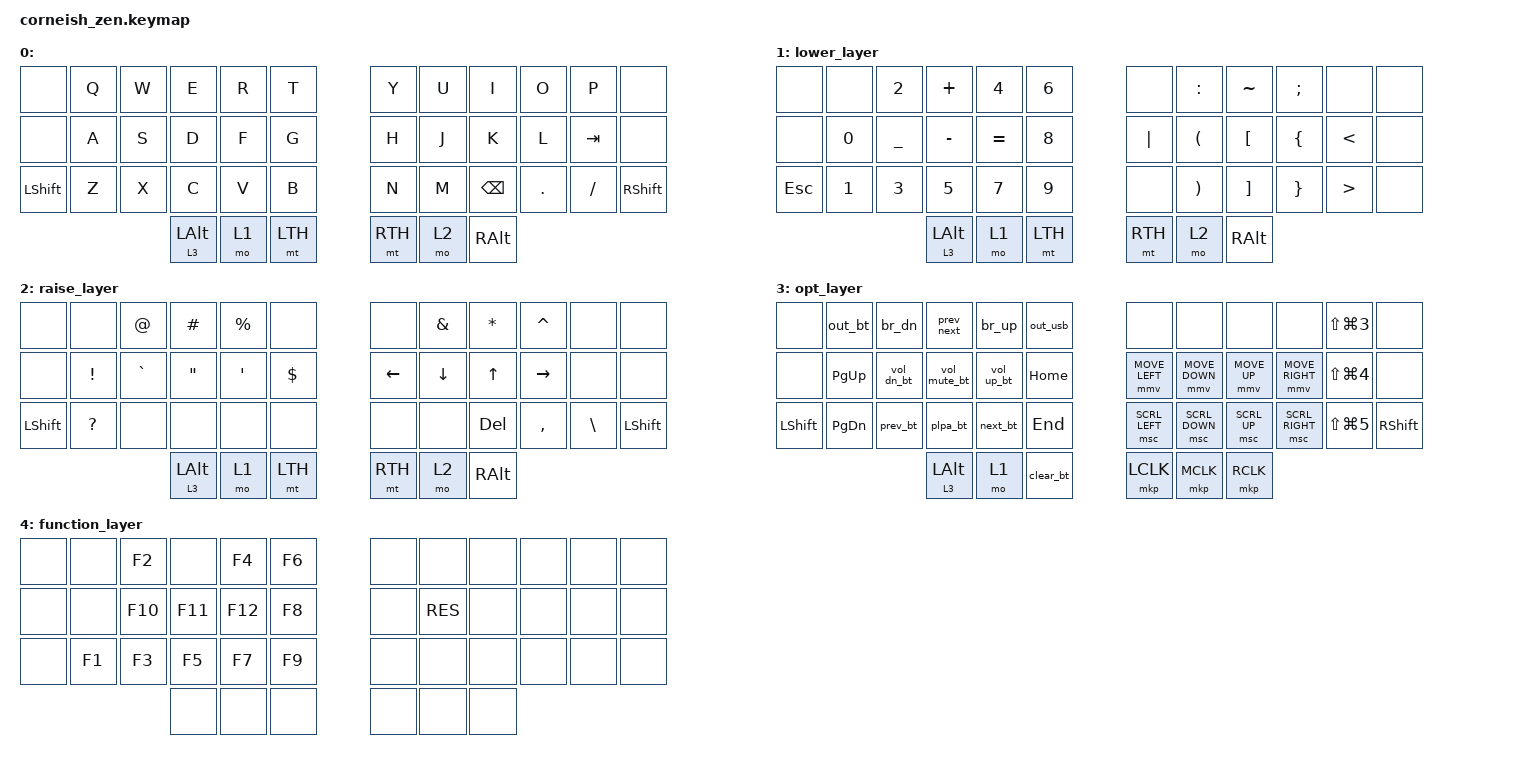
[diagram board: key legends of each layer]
#include <behaviors.dtsi>

#include <dt-bindings/zmk/bt.h>
#include <dt-bindings/zmk/keys.h>
#include <dt-bindings/zmk/pointing.h>
#include <dt-bindings/zmk/outputs.h>
#include <dt-bindings/zmk/behaviors.h>

#define LTH LCTRL SPACE
#define RTH LMETA RET
#define LPK LSHIFT ESC

#define VOL_UP C_VOL_UP
#define VOL_DN C_VOL_DN
#define MUTE   C_MUTE

#define BRI_UP C_BRI_UP
#define EXT_BRI_UP LC(BRI_UP)
#define BRI_DN C_BRI_DN
#define EXT_BRI_DN LC(BRI_DN)

#define PLPA   K_PP
#define NEXT   K_NEXT
#define PREV   K_PREV
#define RES    LC(LA(DEL))

#define LTSHFT &kp LSHIFT
#define RTSHFT &kp RSHIFT

#define ZMK_POINTING_DEFAULT_MOVE_VAL 900
#define ZMK_POINTING_DEFAULT_SCRL_VAL 20

&sk {
  release-after-ms = <3000>;
  quick-release;
};

&mt {
  tapping-term-ms = <160>;
  quick-tap-ms = <200>;
};

&lt {
  tapping-term-ms = <160>;
  quick-tap-ms = <200>;
};

/ {
  behaviors {
    br_dn: brightness_down {
      compatible = "zmk,behavior-mod-morph";
      #binding-cells = <0>;
      bindings = <&kp BRI_DN>, <&kp EXT_BRI_DN>;
      mods = <(MOD_LSFT|MOD_RSFT)>;
    };

    br_up: brightness_up {
      compatible = "zmk,behavior-mod-morph";
      #binding-cells = <0>;
      bindings = <&kp BRI_UP>, <&kp EXT_BRI_UP>;
      mods = <(MOD_LSFT|MOD_RSFT)>;
    };

    lts: layer_tap_sticky {
      compatible = "zmk,behavior-hold-tap";
      #binding-cells = <2>;
      flavor = "tap-preferred";
      tapping-term-ms = <160>;
      bindings = <&mo>, <&sk>;
      display-name = "Layer-Tap-Sticky";
    };

    mts: mod_tap_sticky {
      compatible = "zmk,behavior-hold-tap";
      #binding-cells = <2>;
      flavor = "tap-preferred";
      tapping-term-ms = <160>;
      bindings = <&sk>, <&kp>;
      display-name = "Mod-Tap-Sticky";
    };

    prev_next: prev_and_next {
      compatible = "zmk,behavior-mod-morph";
      #binding-cells = <0>;
      bindings = <&mkp MB4>, <&mkp MB5>;
      mods = <(MOD_LSFT)>;
    };

    vol_dn_bt: volume_down_bluetooth_0 {
      compatible = "zmk,behavior-mod-morph";
      #binding-cells = <0>;
      bindings = <&kp VOL_DN>, <&bt BT_SEL 0>;
      mods = <(MOD_LSFT)>;
    };

    prev_bt: media_previous_bluetooth_0 {
      compatible = "zmk,behavior-mod-morph";
      #binding-cells = <0>;
      bindings = <&kp PREV>, <&bt BT_DISC 0>;
      mods = <(MOD_LSFT)>;
    };

    vol_mute_bt: volume_mute_bluetooth_1 {
      compatible = "zmk,behavior-mod-morph";
      #binding-cells = <0>;
      bindings = <&kp MUTE>, <&bt BT_SEL 1>;
      mods = <(MOD_LSFT)>;
    };

    plpa_bt: play_stop_bluetooth_1 {
      compatible = "zmk,behavior-mod-morph";
      #binding-cells = <0>;
      bindings = <&kp PLPA>, <&bt BT_DISC 1>;
      mods = <(MOD_LSFT)>;
    };

    vol_up_bt: volume_up_bluetooth_2 {
      compatible = "zmk,behavior-mod-morph";
      #binding-cells = <0>;
      bindings = <&kp VOL_UP>, <&bt BT_SEL 2>;
      mods = <(MOD_LSFT)>;
    };

    next_bt: next_bluetooth_2 {
      compatible = "zmk,behavior-mod-morph";
      #binding-cells = <0>;
      bindings = <&kp NEXT>, <&bt BT_DISC 2>;
      mods = <(MOD_LSFT)>;
    };

    out_usb: keyboard_output_usb {
      compatible = "zmk,behavior-mod-morph";
      #binding-cells = <0>;
      bindings = <&none>, <&out OUT_USB>;
      mods = <(MOD_LSFT)>;
    };

    out_bt: keyboard_output_bluetooth {
      compatible = "zmk,behavior-mod-morph";
      #binding-cells = <0>;
      bindings = <&none>, <&out OUT_BLE>;
      mods = <(MOD_LSFT)>;
    };

    clear_bt: bluetooth_clear {
      compatible = "zmk,behavior-mod-morph";
      #binding-cells = <0>;
      bindings = <&none>, <&out BT_CLR>;
      mods = <(MOD_LSFT)>;
    };
  };

  conditional_layers {
    compatible = "zmk,conditional-layers";

    function_layer {
      if-layers = <1 2>;
      then-layer = <4>;
    };
  };

  keymap {
    compatible = "zmk,keymap";

    default_layer {
      label = " ";
      bindings = <
        &none    &kp Q  &kp W  &kp E  &kp R       &kp T                   &kp Y   &kp U  &kp I    &kp O    &kp P     &none
        &none    &kp A  &kp S  &kp D  &kp F       &kp G                   &kp H   &kp J  &kp K    &kp L    &kp TAB   &none
        LTSHFT   &kp Z  &kp X  &kp C  &kp V       &kp B                   &kp N   &kp M  &kp BSPC &kp DOT  &kp FSLH  RTSHFT
                                      &lts 3 LALT &mo 1 &mt LTH   &mt RTH &mo 2   &kp RALT
      >;
    };

    lower_layer {
      bindings = <
        &none   &none   &kp N2    &kp PLUS  &kp N4      &kp N6                   &none    &kp COLON  &kp TILDE  &kp SEMI  &none   &none
        &none   &kp N0  &kp UNDER &kp MINUS &kp EQUAL   &kp N8                   &kp PIPE &kp LPAR   &kp LBKT   &kp LBRC  &kp LT  &none
        &kp ESC &kp N1  &kp N3    &kp N5    &kp N7      &kp N9                   &none    &kp RPAR   &kp RBKT   &kp RBRC  &kp GT  &none
                                            &lts 3 LALT &mo 1  &mt LTH   &mt RTH &mo 2    &kp RALT
      >;
    };

    raise_layer {
      bindings = <
        &none  &none     &kp AT    &kp HASH &kp PRCNT    &none                     &none        &kp AMPS   &kp ASTRK &kp CARET  &none     &none
        &none  &kp EXCL  &kp GRAVE &kp DQT  &kp SQT      &kp DLLR                  &kp LEFT     &kp DOWN   &kp UP    &kp RIGHT  &none     &none
        LTSHFT &kp QMARK &none     &none    &none        &none                     &none        &none      &kp DEL   &kp COMMA  &kp BSLH  LTSHFT
                                            &lts 3 LALT  &mo 1  &mt LTH   &mt RTH  &mo 2        &kp RALT
      >;
    };

    opt_layer {
      bindings = <
        &none   &out_bt      &br_dn      &prev_next   &br_up      &out_usb                            &none          &none           &none        &none            &kp LS(LG(N3))  &none
        &none   &kp PG_UP    &vol_dn_bt  &vol_mute_bt &vol_up_bt  &kp HOME                            &mmv MOVE_LEFT &mmv MOVE_DOWN  &mmv MOVE_UP &mmv MOVE_RIGHT  &kp LS(LG(N4))  &none
        LTSHFT  &kp PG_DN    &prev_bt    &plpa_bt     &next_bt    &kp END                             &msc SCRL_LEFT &msc SCRL_DOWN  &msc SCRL_UP &msc SCRL_RIGHT  &kp LS(LG(N5))  RTSHFT
                                                      &lts 3 LALT &mo 1   &clear_bt        &mkp LCLK  &mkp MCLK      &mkp RCLK
      >;
    };

    function_layer {
      bindings = <
        &none  &none   &kp F2   &none   &kp F4    &kp F6                     &none  &none    &none  &none  &none  &none
        &none  &none   &kp F10  &kp F11 &kp F12   &kp F8                     &none  &kp RES  &none  &none  &none  &none
        &none  &kp F1  &kp F3   &kp F5  &kp F7    &kp F9                     &none  &none    &none  &none  &none  &none
                                        &none     &none  &none        &none  &none  &none
      >;
    };
  };
};
